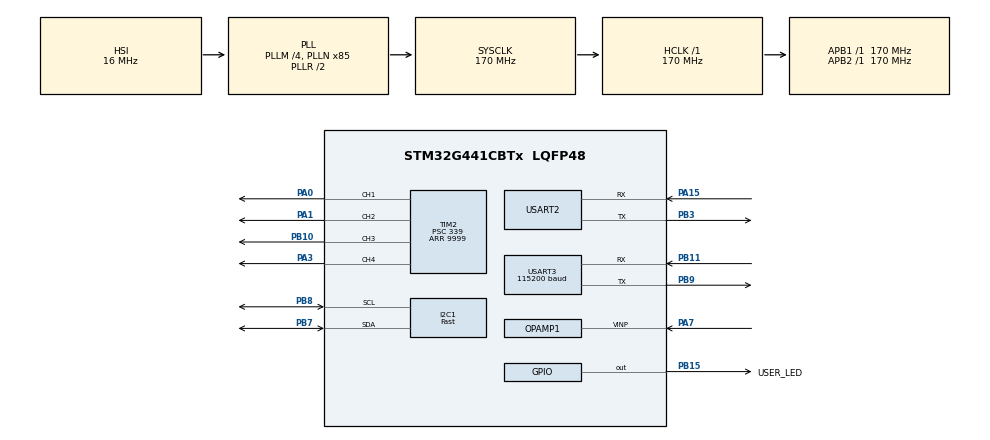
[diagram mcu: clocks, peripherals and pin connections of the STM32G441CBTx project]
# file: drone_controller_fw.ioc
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ADC1.Channel-1\#ChannelRegularConversion=ADC_CHANNEL_VOPAMP1
ADC1.NbrOfConversionFlag=1
ADC1.OffsetNumber-1\#ChannelRegularConversion=ADC_OFFSET_NONE
ADC1.Rank-1\#ChannelRegularConversion=1
ADC1.SamplingTime-1\#ChannelRegularConversion=ADC_SAMPLETIME_2CYCLES_5
ADC1.master=1
Dma.ADC1.1.Direction=DMA_PERIPH_TO_MEMORY
Dma.ADC1.1.EventEnable=DISABLE
Dma.ADC1.1.Instance=DMA1_Channel2
Dma.ADC1.1.MemDataAlignment=DMA_MDATAALIGN_HALFWORD
Dma.ADC1.1.MemInc=DMA_MINC_ENABLE
Dma.ADC1.1.Mode=DMA_CIRCULAR
Dma.ADC1.1.PeriphDataAlignment=DMA_PDATAALIGN_HALFWORD
Dma.ADC1.1.PeriphInc=DMA_PINC_DISABLE
Dma.ADC1.1.Polarity=HAL_DMAMUX_REQ_GEN_RISING
Dma.ADC1.1.Priority=DMA_PRIORITY_LOW
Dma.ADC1.1.RequestNumber=1
Dma.ADC1.1.SignalID=NONE
Dma.ADC1.1.SyncEnable=DISABLE
Dma.ADC1.1.SyncPolarity=HAL_DMAMUX_SYNC_NO_EVENT
Dma.ADC1.1.SyncRequestNumber=1
Dma.ADC1.1.SyncSignalID=NONE
Dma.Request0=USART3_TX
Dma.Request1=ADC1
Dma.USART3_TX.0.Direction=DMA_MEMORY_TO_PERIPH
Dma.USART3_TX.0.EventEnable=DISABLE
Dma.USART3_TX.0.Instance=DMA1_Channel1
Dma.USART3_TX.0.MemDataAlignment=DMA_MDATAALIGN_BYTE
Dma.USART3_TX.0.MemInc=DMA_MINC_ENABLE
Dma.USART3_TX.0.Mode=DMA_NORMAL
Dma.USART3_TX.0.PeriphDataAlignment=DMA_PDATAALIGN_BYTE
Dma.USART3_TX.0.PeriphInc=DMA_PINC_DISABLE
Dma.USART3_TX.0.Polarity=HAL_DMAMUX_REQ_GEN_RISING
Dma.USART3_TX.0.Priority=DMA_PRIORITY_LOW
Dma.USART3_TX.0.RequestNumber=1
Dma.USART3_TX.0.SignalID=NONE
Dma.USART3_TX.0.SyncEnable=DISABLE
Dma.USART3_TX.0.SyncPolarity=HAL_DMAMUX_SYNC_NO_EVENT
Dma.USART3_TX.0.SyncRequestNumber=1
Dma.USART3_TX.0.SyncSignalID=NONE
I2C1.I2C_Speed_Mode=I2C_Fast
I2C1.Speed=200
I2C1.Timing=0x40301391
Mcu.Family=STM32G4
Mcu.Name=STM32G441CBTx
Mcu.Package=LQFP48
NVIC.DMA1_Channel1_IRQn=true\:0\:0\:false\:false\:true\:false\:true\:true
NVIC.DMA1_Channel2_IRQn=true\:0\:0\:false\:false\:true\:false\:true\:true
NVIC.I2C1_EV_IRQn=true\:0\:0\:false\:false\:true\:true\:true\:true
NVIC.PriorityGroup=NVIC_PRIORITYGROUP_4
NVIC.TIM2_IRQn=true\:0\:0\:false\:false\:true\:true\:true\:true
NVIC.TIM6_DAC_IRQn=true\:15\:0\:false\:false\:true\:false\:true\:true
NVIC.TIM7_IRQn=true\:0\:0\:false\:false\:true\:true\:true\:true
NVIC.TimeBase=TIM6_DAC_IRQn
NVIC.TimeBaseIP=TIM6
NVIC.USART2_IRQn=true\:0\:0\:false\:false\:true\:true\:true\:true
NVIC.USART3_IRQn=true\:15\:0\:true\:false\:true\:true\:true\:true
OPAMP1.PgaGain=OPAMP_PGA_GAIN_16_OR_MINUS_15
PA0.Signal=S_TIM2_CH1
PA1.Signal=S_TIM2_CH2
PA13.Mode=Serial_Wire
PA13.Signal=SYS_JTMS-SWDIO
PA14.Mode=Serial_Wire
PA14.Signal=SYS_JTCK-SWCLK
PA15.Mode=Asynchronous
PA15.Signal=USART2_RX
PA3.Signal=S_TIM2_CH4
PA7.Mode=PGA_Internally_Connected
PA7.Signal=OPAMP1_VINP
PB10.Signal=S_TIM2_CH3
PB11.Mode=Asynchronous
PB11.Signal=USART3_RX
PB15.GPIO_Label=USER_LED
PB15.Signal=GPIO_Output
PB3.Mode=Asynchronous
PB3.Signal=USART2_TX
PB7.GPIO_Pu=GPIO_NOPULL
PB7.Mode=I2C
PB7.Signal=I2C1_SDA
PB8-BOOT0.GPIO_Pu=GPIO_NOPULL
PB8-BOOT0.Mode=I2C
PB8-BOOT0.Signal=I2C1_SCL
PB9.Mode=Asynchronous
PB9.Signal=USART3_TX
ProjectManager.HeapSize=0x200
ProjectManager.StackSize=0x400
ProjectManager.TargetToolchain=STM32CubeIDE
RCC.ADC12Freq_Value=170000000
RCC.AHBFreq_Value=170000000
RCC.APB1Freq_Value=170000000
RCC.APB1TimFreq_Value=170000000
RCC.APB2Freq_Value=170000000
RCC.APB2TimFreq_Value=170000000
RCC.CortexFreq_Value=170000000
RCC.EXTERNAL_CLOCK_VALUE=12288000
RCC.HCLKFreq_Value=170000000
RCC.HSE_VALUE=8000000
RCC.HSI48_VALUE=48000000
RCC.HSI_VALUE=16000000
RCC.LSE_VALUE=32768
RCC.PLLM=RCC_PLLM_DIV4
RCC.PLLN=85
RCC.SYSCLKFreq_VALUE=170000000
RCC.SYSCLKSource=RCC_SYSCLKSOURCE_PLLCLK
RCC.USBFreq_Value=170000000
RCC.VCOOutputFreq_Value=340000000
SH.S_TIM2_CH1.0=TIM2_CH1,PWM Generation1 CH1
SH.S_TIM2_CH2.0=TIM2_CH2,PWM Generation2 CH2
SH.S_TIM2_CH3.0=TIM2_CH3,PWM Generation3 CH3
SH.S_TIM2_CH4.0=TIM2_CH4,PWM Generation4 CH4
TIM2.Channel-PWM\ Generation1\ CH1=TIM_CHANNEL_1
TIM2.Channel-PWM\ Generation2\ CH2=TIM_CHANNEL_2
TIM2.Channel-PWM\ Generation3\ CH3=TIM_CHANNEL_3
TIM2.Channel-PWM\ Generation4\ CH4=TIM_CHANNEL_4
TIM2.PeriodNoDither=9999
TIM2.Prescaler=339
TIM2.PulseNoDither_1=500
TIM2.PulseNoDither_2=500
TIM2.PulseNoDither_3=500
TIM2.PulseNoDither_4=500
TIM7.Prescaler=1699
USART2.VirtualMode-Asynchronous=VM_ASYNC
USART3.BaudRate=115200
USART3.StopBits=STOPBITS_2
USART3.VirtualMode-Asynchronous=VM_ASYNC
VP_ADC1_OPAMP_INTERNAL1.Mode=IN-OPAMP1
VP_SYS_VS_DBSignals.Mode=DisableDeadBatterySignals
VP_SYS_VS_tim6.Mode=TIM6
VP_TIM1_VS_ClockSourceINT.Mode=Internal
VP_TIM7_VS_ClockSourceINT.Mode=Enable_Timer
board=custom

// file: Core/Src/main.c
/* USER CODE BEGIN Header */
/**
  ******************************************************************************
  * @file           : main.c
  * @brief          : Main program body
  ******************************************************************************
  * @attention
  *
  * Copyright (c) 2022 STMicroelectronics.
  * All rights reserved.
  *
  * This software is licensed under terms that can be found in the LICENSE file
  * in the root directory of this software component.
  * If no LICENSE file comes with this software, it is provided AS-IS.
  *
  ******************************************************************************
  */
/* USER CODE END Header */
#include "main.h"
#include "adc.h"
#include "dma.h"
#include "i2c.h"
#include "opamp.h"
#include "tim.h"
#include "usart.h"
#include "gpio.h"

/* USER CODE BEGIN Includes */
#include "FreeRTOS.h"
#include "task.h"
#include <stdbool.h>
#include "drone.h"
/* USER CODE END Includes */

void SystemClock_Config(void);

int main(void)
{

  /* MCU Configuration--------------------------------------------------------*/

  /* Reset of all peripherals, Initializes the Flash interface and the Systick. */
  HAL_Init();

  /* Configure the system clock */
  SystemClock_Config();

  /* Initialize all configured peripherals */
  MX_GPIO_Init();
  MX_DMA_Init();
  MX_I2C1_Init();
  MX_TIM2_Init();
  MX_TIM7_Init();
  MX_USART2_UART_Init();
  MX_USART3_UART_Init();
  MX_TIM1_Init();
  MX_ADC1_Init();
  MX_OPAMP1_Init();
  /* USER CODE BEGIN 2 */
    drone_init();

  // FreeRTOS stuff
  vTaskStartScheduler();
  /* USER CODE END 2 */

  /* Infinite loop */
  while (1)
  {

  }
}

void SystemClock_Config(void)
{
  RCC_OscInitTypeDef RCC_OscInitStruct = {0};
  RCC_ClkInitTypeDef RCC_ClkInitStruct = {0};

  /** Configure the main internal regulator output voltage
  */
  HAL_PWREx_ControlVoltageScaling(PWR_REGULATOR_VOLTAGE_SCALE1_BOOST);

  /** Initializes the RCC Oscillators according to the specified parameters
  * in the RCC_OscInitTypeDef structure.
  */
  RCC_OscInitStruct.OscillatorType = RCC_OSCILLATORTYPE_HSI;
  RCC_OscInitStruct.HSIState = RCC_HSI_ON;
  RCC_OscInitStruct.HSICalibrationValue = RCC_HSICALIBRATION_DEFAULT;
  RCC_OscInitStruct.PLL.PLLState = RCC_PLL_ON;
  RCC_OscInitStruct.PLL.PLLSource = RCC_PLLSOURCE_HSI;
  RCC_OscInitStruct.PLL.PLLM = RCC_PLLM_DIV4;
  RCC_OscInitStruct.PLL.PLLN = 85;
  RCC_OscInitStruct.PLL.PLLP = RCC_PLLP_DIV2;
  RCC_OscInitStruct.PLL.PLLQ = RCC_PLLQ_DIV2;
  RCC_OscInitStruct.PLL.PLLR = RCC_PLLR_DIV2;
  if (HAL_RCC_OscConfig(&RCC_OscInitStruct) != HAL_OK)
  {
    Error_Handler();
  }

  /** Initializes the CPU, AHB and APB buses clocks
  */
  RCC_ClkInitStruct.ClockType = RCC_CLOCKTYPE_HCLK|RCC_CLOCKTYPE_SYSCLK
                              |RCC_CLOCKTYPE_PCLK1|RCC_CLOCKTYPE_PCLK2;
  RCC_ClkInitStruct.SYSCLKSource = RCC_SYSCLKSOURCE_PLLCLK;
  RCC_ClkInitStruct.AHBCLKDivider = RCC_SYSCLK_DIV1;
  RCC_ClkInitStruct.APB1CLKDivider = RCC_HCLK_DIV1;
  RCC_ClkInitStruct.APB2CLKDivider = RCC_HCLK_DIV1;

  if (HAL_RCC_ClockConfig(&RCC_ClkInitStruct, FLASH_LATENCY_4) != HAL_OK)
  {
    Error_Handler();
  }
}

/* USER CODE BEGIN 4 */
#define HIGH_RES_TIMER_PERIOD 65535
volatile uint64_t high_res_time = 0;
volatile uint32_t aux = 0;
volatile int32_t tim_diff;
/* USER CODE END 4 */

void HAL_TIM_PeriodElapsedCallback(TIM_HandleTypeDef *htim)
{
  /* USER CODE BEGIN Callback 0 */

  if(htim->Instance == TIM7)
  {
      tim_diff = aux - high_res_time/100;
      high_res_time += HIGH_RES_TIMER_PERIOD;
      aux = HAL_GetTick();
  }
  /* USER CODE END Callback 0 */
  if (htim->Instance == TIM6) {
    HAL_IncTick();
  }
}

void Error_Handler(void)
{
  __disable_irq();
  while (1)
  {
  }
}
